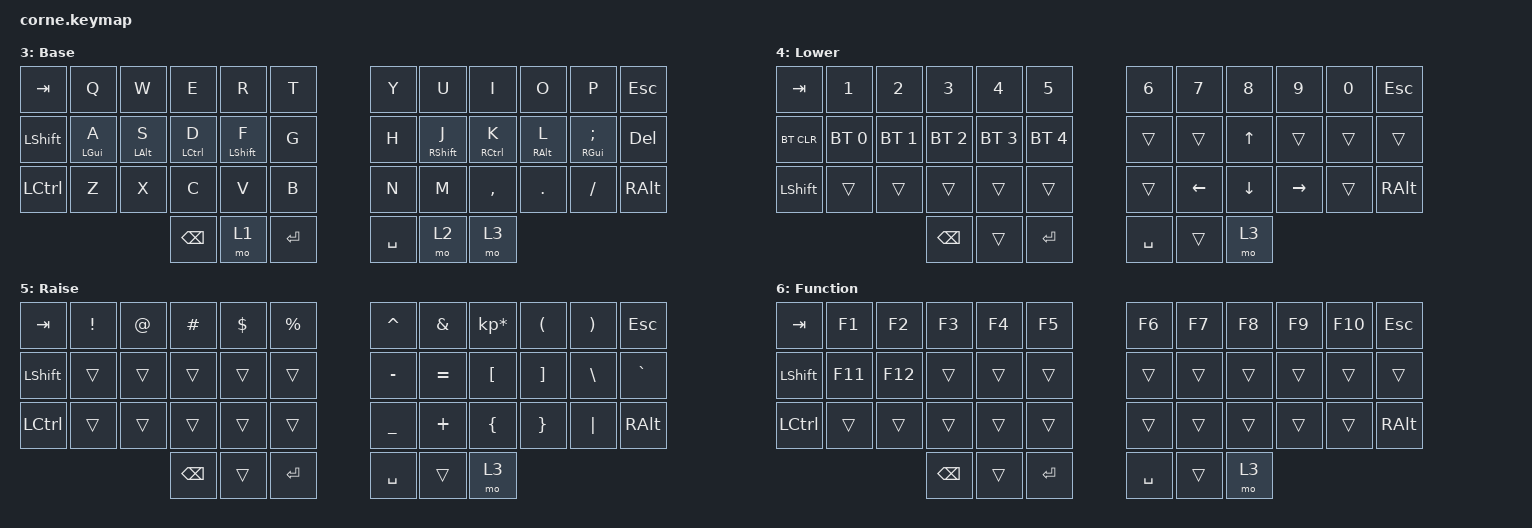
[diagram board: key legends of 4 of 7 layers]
/*
 * Copyright (c) 2020 The ZMK Contributors
 *
 * SPDX-License-Identifier: MIT
 *
 * Layer/profile mapping:
 * - BT Profile 0: Mac (OSX) layer (GACS home row mods)
 * - BT Profile 1: Windows layer (CAGS home row mods)
 * - BT Profile 2: Linux layer (CAGS home row mods)
 *
 * Use ZMK's Bluetooth profile switching to select the correct OS layer.
 *
 * Home row mod behaviors and modifier order are defined using macros for maintainability.
 */

#include <behaviors.dtsi>
#include <dt-bindings/zmk/keys.h>
#include <dt-bindings/zmk/bt.h>

#define PRIOR_IDLE_MS 150
#define TAPPING_TERM_MS 280
#define QUICK_TAP_MS 175

// Shared home row mod behaviors for left and right hands
#define HOME_ROW_MOD_LEFT(name) \
	name: name { \
		compatible = "zmk,behavior-hold-tap"; \
		#binding-cells = <2>; \
		flavor = "balanced"; \
		require-prior-idle-ms = <PRIOR_IDLE_MS>; \
		tapping-term-ms = <TAPPING_TERM_MS>; \
		quick-tap-ms = <QUICK_TAP_MS>; \
		bindings = <&kp>, <&kp>; \
		hold-trigger-key-positions = <6 7 8 9 10 11 18 19 20 21 22 23 30 31 32 33 34 35 39 40 41>; \
		hold-trigger-on-release; \
	}

#define HOME_ROW_MOD_RIGHT(name) \
	name: name { \
		compatible = "zmk,behavior-hold-tap"; \
		#binding-cells = <2>; \
		flavor = "balanced"; \
		require-prior-idle-ms = <PRIOR_IDLE_MS>; \
		tapping-term-ms = <TAPPING_TERM_MS>; \
		quick-tap-ms = <QUICK_TAP_MS>; \
		bindings = <&kp>, <&kp>; \
		hold-trigger-key-positions = <0 1 2 3 4 5 12 13 14 15 16 17 24 25 26 27 28 29 36 37 38>; \
		hold-trigger-on-release; \
	}

/ {
	behaviors {
		// Instantiate shared home row mod behaviors
		HOME_ROW_MOD_LEFT(hml);
		HOME_ROW_MOD_RIGHT(hmr);
	};

	// OS-specific home row mod macros
	#define HML_MAC &hml LGUI A &hml LALT S &hml LCTRL D &hml LSHFT F
	#define HMR_MAC &hmr RSHFT J &hmr RCTRL K &hmr RALT L &hmr RGUI SEMI

	#define HML_WIN &hml LCTRL A &hml LALT S &hml LGUI D &hml LSHFT F
	#define HMR_WIN &hmr RSHFT J &hmr RGUI K &hmr RALT L &hmr RCTRL SEMI

	#define HML_LIN &hml LCTRL A &hml LALT S &hml LGUI D &hml LSHFT F
	#define HMR_LIN &hmr RSHFT J &hmr RGUI K &hmr RALT L &hmr RCTRL SEMI

	keymap {
		compatible = "zmk,keymap";

		// Mac (OSX) Layer - BT Profile 0
		mac_layer {
			display-name = "Mac (OSX)";
			bindings = <
				&kp TAB   &kp Q         &kp W         &kp E         &kp R         &kp T   &kp Y   &kp U          &kp I          &kp O          &kp P         &kp ESC
				&kp LSHFT HML_MAC &kp G   &kp H   HMR_MAC &kp DEL
				&kp LCTRL &kp Z         &kp X         &kp C         &kp V         &kp B   &kp N   &kp M          &kp COMMA      &kp DOT        &kp FSLH      &kp RALT
				&kp BSPC &mo 1 &kp RET   &kp SPACE &mo 2 &mo 3
			>;
		};

		// Windows Layer - BT Profile 1
		win_layer {
			display-name = "Windows";
			bindings = <
				&kp TAB   &kp Q         &kp W         &kp E         &kp R         &kp T   &kp Y   &kp U          &kp I          &kp O          &kp P         &kp ESC
				&kp LSHFT HML_WIN &kp G   &kp H   HMR_WIN &kp DEL
				&kp LCTRL &kp Z         &kp X         &kp C         &kp V         &kp B   &kp N   &kp M          &kp COMMA      &kp DOT        &kp FSLH      &kp RALT
				&kp BSPC &mo 1 &kp RET   &kp SPACE &mo 2 &mo 3
			>;
		};

		// Linux Layer - BT Profile 2
		linux_layer {
			display-name = "Linux";
			bindings = <
				&kp TAB   &kp Q         &kp W         &kp E         &kp R         &kp T   &kp Y   &kp U          &kp I          &kp O          &kp P         &kp ESC
				&kp LSHFT HML_LIN &kp G   &kp H   HMR_LIN &kp DEL
				&kp LCTRL &kp Z         &kp X         &kp C         &kp V         &kp B   &kp N   &kp M          &kp COMMA      &kp DOT        &kp FSLH      &kp RALT
				&kp BSPC &mo 1 &kp RET   &kp SPACE &mo 2 &mo 3
			>;
		};

		default_layer {
			// -----------------------------------------------------------------------------------------
			// | TAB  |  Q  |  W  |  E  |  R  |  T  |     |  Y  |  U  |  I  |  O  |  P  | ESC  |
			// |SHFT  |GUI/A|ALT/S|CTL/D|SFT/F|  G  |     |  H  |SFT/J|CTL/K|ALT/L|GUI/;| DEL  |
			// |CTRL  |  Z  |  X  |  C  |  V  |  B  |     |  N  |  M  |  ,  |  .  |  /  | RALT |
			//                 | BSPC |LWR| RET |     | SPC |RSE| FN  |
			display-name = "Base";
			bindings = <
				&kp TAB   &kp Q       &kp W       &kp E        &kp R        &kp T   &kp Y   &kp U        &kp I        &kp O        &kp P         &kp ESC
				&kp LSHFT &hml LGUI A &hml LALT S &hml LCTRL D &hml LSHFT F &kp G   &kp H   &hmr RSHFT J &hmr RCTRL K &hmr RALT L  &hmr RGUI SEMI &kp DEL
				&kp LCTRL &kp Z       &kp X       &kp C        &kp V        &kp B   &kp N   &kp M        &kp COMMA    &kp DOT      &kp FSLH      &kp RALT
				&kp BSPC &mo 1 &kp RET   &kp SPACE &mo 2 &mo 3
			>;
		};

		lower_layer {
			// -----------------------------------------------------------------------------------------
			// | TAB  |  1  |  2  |  3  |  4  |  5  |     |  6  |  7  |  8  |  9  |  0  | ESC  |
			// |BTCLR |BT1  |BT2  |BT3  |BT4  |BT5  |     |     |     | UP  |     |     |      |
			// |SHFT  |     |     |     |     |     |     |LFT  |DWN  |RGT  |     |     | RALT |
			//                 | BSPC |   | RET |     | SPC |   | FN  |
			display-name = "Lower";
			bindings = <
				&kp TAB    &kp N1       &kp N2       &kp N3       &kp N4       &kp N5         &kp N6   &kp N7      &kp N8      &kp N9       &kp N0 &kp ESC
				&bt BT_CLR &bt BT_SEL 0 &bt BT_SEL 1 &bt BT_SEL 2 &bt BT_SEL 3 &bt BT_SEL 4   &trans   &trans      &kp UP      &trans       &trans &trans
				&kp LSHFT  &trans       &trans       &trans       &trans       &trans         &trans   &kp LEFT    &kp DOWN   &kp RIGHT        &trans &kp RALT
				&kp BSPC   &trans       &kp RET      &kp SPACE    &trans       &mo 3
			>;
		};

		raise_layer {
			// -----------------------------------------------------------------------------------------
			// | TAB  |  !  |  @  |  #  |  $  |  %  |     |  ^  |  &  |  *  |  (  |  )  | ESC  |
			// |SHFT  |     |     |     |     |     |     | -   | =   | [   | ]   | \   |  `   |
			// |CTRL  |     |     |     |     |     |     | _   | +   | {   | }   | |   | RALT |
			//                 | BSPC |   | RET |     | SPC |   | FN  |
			display-name = "Raise";
			bindings = <
				&kp TAB   &kp EXCL &kp AT &kp HASH &kp DLLR &kp PRCNT   &kp CARET &kp AMPS  &kp KP_MULTIPLY &kp LPAR &kp RPAR &kp ESC
				&kp LSHFT &trans   &trans &trans   &trans   &trans      &kp MINUS &kp EQUAL &kp LBKT        &kp RBKT &kp BSLH &kp GRAVE
				&kp LCTRL &trans   &trans &trans   &trans   &trans      &kp UNDER &kp PLUS  &kp LBRC        &kp RBRC &kp PIPE &kp RALT
				&kp BSPC  &trans   &kp RET   &kp SPACE   &trans    &mo 3
			>;
		};

		function_layer {
			// -----------------------------------------------------------------------------------------
			// | TAB  | F1  | F2  | F3  | F4  | F5  |     | F6  | F7  | F8  | F9  | F10 | ESC  |
			// |SHFT  | F11 | F12 |     |     |     |     |     |     |     |     |     |      |
			// |CTRL  |     |     |     |     |     |     |     |     |     |     |     | RALT |
			//                 | BSPC |   | RET |     | SPC |   | FN  |
			display-name = "Function";
			bindings = <
				&kp TAB   &kp F1  &kp F2  &kp F3  &kp F4  &kp F5    &kp F6  &kp F7  &kp F8  &kp F9  &kp F10 &kp ESC
				&kp LSHFT &kp F11 &kp F12 &trans  &trans  &trans    &trans  &trans  &trans  &trans  &trans  &trans
				&kp LCTRL &trans  &trans  &trans  &trans  &trans    &trans  &trans  &trans  &trans  &trans  &kp RALT
				&kp BSPC  &trans  &kp RET    &kp SPACE &trans &mo 3
			>;
		};

		extra_1 {
			status = "reserved";
		};

		extra_2 {
			status = "reserved";
		};
	};
};
